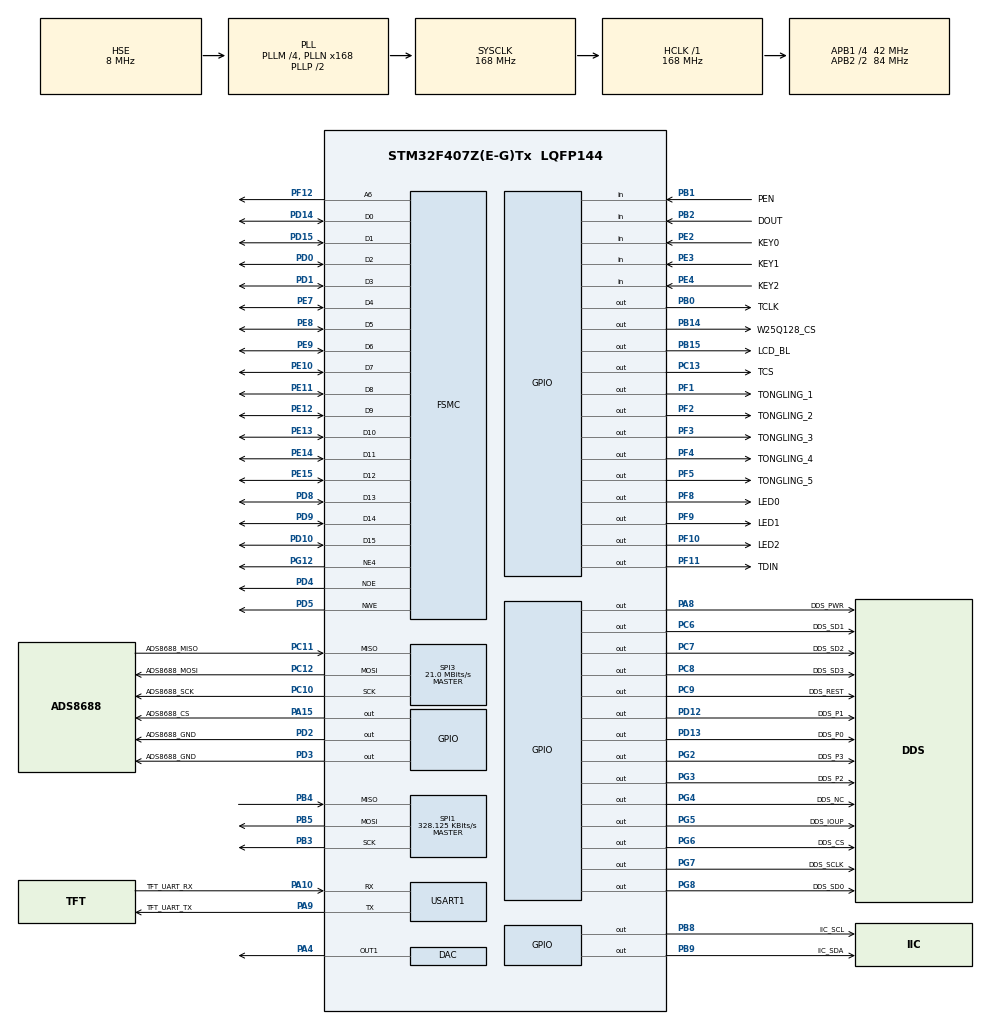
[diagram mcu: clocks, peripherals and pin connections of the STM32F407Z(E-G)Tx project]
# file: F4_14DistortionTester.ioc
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Dma.Request0=SPI3_RX
Dma.Request1=SPI3_TX
Dma.SPI3_RX.0.Direction=DMA_PERIPH_TO_MEMORY
Dma.SPI3_RX.0.FIFOMode=DMA_FIFOMODE_DISABLE
Dma.SPI3_RX.0.Instance=DMA1_Stream0
Dma.SPI3_RX.0.MemDataAlignment=DMA_MDATAALIGN_HALFWORD
Dma.SPI3_RX.0.MemInc=DMA_MINC_ENABLE
Dma.SPI3_RX.0.Mode=DMA_NORMAL
Dma.SPI3_RX.0.PeriphDataAlignment=DMA_PDATAALIGN_HALFWORD
Dma.SPI3_RX.0.PeriphInc=DMA_PINC_DISABLE
Dma.SPI3_RX.0.Priority=DMA_PRIORITY_LOW
Dma.SPI3_TX.1.Direction=DMA_MEMORY_TO_PERIPH
Dma.SPI3_TX.1.FIFOMode=DMA_FIFOMODE_DISABLE
Dma.SPI3_TX.1.Instance=DMA1_Stream5
Dma.SPI3_TX.1.MemDataAlignment=DMA_MDATAALIGN_HALFWORD
Dma.SPI3_TX.1.MemInc=DMA_MINC_ENABLE
Dma.SPI3_TX.1.Mode=DMA_NORMAL
Dma.SPI3_TX.1.PeriphDataAlignment=DMA_PDATAALIGN_HALFWORD
Dma.SPI3_TX.1.PeriphInc=DMA_PINC_DISABLE
Dma.SPI3_TX.1.Priority=DMA_PRIORITY_LOW
FREERTOS.CountingSemaphores01=TFT_RX_LED,10,Dynamic,NULL;TFT_TX_LED,10,Dynamic,NULL
FREERTOS.Queues01=USART1_RX,5,30,1,Dynamic,NULL,NULL
FREERTOS.Tasks01=defaultTask,8,128,StartDefaultTask,Default,NULL,Dynamic,NULL,NULL;LED0_Toggle,48,128,StartLED0Toggle,As weak,NULL,Dynamic,NULL,NULL;LED1_Toggle,48,128,StartLED1Toggle,As weak,NULL,Dynamic,NULL,NULL;TFT_CMD_Process,40,256,TFT_CMD_Process_Start,As weak,NULL,Dynamic,NULL,NULL;FLASH_Data_Auto,24,128,FLASH_Data_AutoUpdate_Start,As weak,NULL,Dynamic,NULL,NULL;LED2_Toggle,48,128,StartLED2Toggle,As weak,NULL,Dynamic,NULL,NULL;MainTask,39,1024,MainTask_Start,As weak,NULL,Dynamic,NULL,NULL
FREERTOS.configENABLE_FPU=1
FREERTOS.configUSE_NEWLIB_REENTRANT=1
FSMC.AddressSetupTime1=0x0f
FSMC.BusTurnAroundDuration1=0
FSMC.DataSetupTime1=60
FSMC.ExtendedAddressSetupTime1=9
FSMC.ExtendedBusTurnAroundDuration1=0
FSMC.ExtendedDataSetupTime1=8
FSMC.ExtendedMode1=FSMC_EXTENDED_MODE_ENABLE
Mcu.Family=STM32F4
Mcu.Name=STM32F407Z(E-G)Tx
Mcu.Package=LQFP144
NVIC.DMA1_Stream0_IRQn=true\:0\:0\:true\:false\:true\:false\:false\:true
NVIC.DMA1_Stream5_IRQn=true\:0\:0\:true\:false\:true\:false\:false\:true
NVIC.PriorityGroup=NVIC_PRIORITYGROUP_4
NVIC.TIM1_UP_TIM10_IRQn=true\:1\:0\:true\:false\:true\:false\:true\:true
NVIC.TIM2_IRQn=true\:4\:0\:true\:false\:true\:false\:false\:true
NVIC.TimeBase=TIM2_IRQn
NVIC.TimeBaseIP=TIM2
NVIC.USART1_IRQn=true\:6\:0\:true\:false\:true\:true\:true\:true
PA0-WKUP.Mode=SYS_WakeUp0
PA0-WKUP.Signal=SYS_WKUP
PA10.GPIO_Label=TFT_UART_RX
PA10.Mode=Asynchronous
PA10.Signal=USART1_RX
PA13.Mode=Serial_Wire
PA13.Signal=SYS_JTMS-SWDIO
PA14.Mode=Serial_Wire
PA14.Signal=SYS_JTCK-SWCLK
PA15.GPIO_Label=ADS8688_CS
PA15.GPIO_PuPd=GPIO_PULLUP
PA15.GPIO_Speed=GPIO_SPEED_FREQ_VERY_HIGH
PA15.PinState=GPIO_PIN_SET
PA15.Signal=GPIO_Output
PA4.Signal=COMP_DAC1_group
PA8.GPIO_Label=DDS_PWR
PA8.GPIO_Speed=GPIO_SPEED_FREQ_VERY_HIGH
PA8.Signal=GPIO_Output
PA9.GPIO_Label=TFT_UART_TX
PA9.Mode=Asynchronous
PA9.Signal=USART1_TX
PB0.GPIO_Label=TCLK
PB0.GPIO_PuPd=GPIO_PULLUP
PB0.GPIO_Speed=GPIO_SPEED_FREQ_VERY_HIGH
PB0.Signal=GPIO_Output
PB1.GPIO_Label=PEN
PB1.GPIO_Mode=GPIO_MODE_INPUT
PB1.GPIO_PuPd=GPIO_PULLUP
PB1.Signal=GPIO_Input
PB14.GPIO_Label=W25Q128_CS
PB14.GPIO_PuPd=GPIO_PULLUP
PB14.GPIO_Speed=GPIO_SPEED_FREQ_VERY_HIGH
PB14.PinState=GPIO_PIN_SET
PB14.Signal=GPIO_Output
PB15.GPIO_Label=LCD_BL
PB15.GPIO_PuPd=GPIO_PULLUP
PB15.GPIO_Speed=GPIO_SPEED_FREQ_MEDIUM
PB15.Signal=GPIO_Output
PB2.GPIO_Label=DOUT
PB2.GPIO_PuPd=GPIO_PULLUP
PB2.Signal=GPIO_Input
PB3.GPIO_PuPd=GPIO_PULLUP
PB3.GPIO_Speed=GPIO_SPEED_FREQ_VERY_HIGH
PB3.Mode=Full_Duplex_Master
PB3.Signal=SPI1_SCK
PB4.GPIO_PuPd=GPIO_PULLUP
PB4.GPIO_Speed=GPIO_SPEED_FREQ_VERY_HIGH
PB4.Mode=Full_Duplex_Master
PB4.Signal=SPI1_MISO
PB5.GPIO_PuPd=GPIO_PULLUP
PB5.GPIO_Speed=GPIO_SPEED_FREQ_VERY_HIGH
PB5.Mode=Full_Duplex_Master
PB5.Signal=SPI1_MOSI
PB8.GPIO_Label=IIC_SCL
PB8.GPIO_PuPd=GPIO_PULLUP
PB8.GPIO_Speed=GPIO_SPEED_FREQ_VERY_HIGH
PB8.Signal=GPIO_Output
PB9.GPIO_Label=IIC_SDA
PB9.GPIO_PuPd=GPIO_PULLUP
PB9.GPIO_Speed=GPIO_SPEED_FREQ_VERY_HIGH
PB9.Signal=GPIO_Output
PC10.GPIO_Label=ADS8688_SCK
PC10.Mode=Full_Duplex_Master
PC10.Signal=SPI3_SCK
PC11.GPIO_Label=ADS8688_MISO
PC11.Mode=Full_Duplex_Master
PC11.Signal=SPI3_MISO
PC12.GPIO_Label=ADS8688_MOSI
PC12.Mode=Full_Duplex_Master
PC12.Signal=SPI3_MOSI
PC13-ANTI_TAMP.GPIO_Label=TCS
PC13-ANTI_TAMP.Signal=GPIO_Output
PC6.GPIO_Label=DDS_SD1
PC6.GPIO_Speed=GPIO_SPEED_FREQ_VERY_HIGH
PC6.Signal=GPIO_Output
PC7.GPIO_Label=DDS_SD2
PC7.GPIO_Speed=GPIO_SPEED_FREQ_VERY_HIGH
PC7.Signal=GPIO_Output
PC8.GPIO_Label=DDS_SD3
PC8.GPIO_Speed=GPIO_SPEED_FREQ_VERY_HIGH
PC8.Signal=GPIO_Output
PC9.GPIO_Label=DDS_REST
PC9.GPIO_Speed=GPIO_SPEED_FREQ_VERY_HIGH
PC9.Signal=GPIO_Output
PD0.GPIO_PuPd=GPIO_PULLUP
PD0.Signal=FSMC_D2_DA2
PD1.GPIO_PuPd=GPIO_PULLUP
PD1.Signal=FSMC_D3_DA3
PD10.GPIO_PuPd=GPIO_PULLUP
PD10.Signal=FSMC_D15_DA15
PD12.GPIO_Label=DDS_P1
PD12.GPIO_Speed=GPIO_SPEED_FREQ_VERY_HIGH
PD12.Signal=GPIO_Output
PD13.GPIO_Label=DDS_P0
PD13.GPIO_Speed=GPIO_SPEED_FREQ_VERY_HIGH
PD13.Signal=GPIO_Output
PD14.GPIO_PuPd=GPIO_PULLUP
PD14.Signal=FSMC_D0_DA0
PD15.GPIO_PuPd=GPIO_PULLUP
PD15.Signal=FSMC_D1_DA1
PD2.GPIO_Label=ADS8688_GND
PD2.Signal=GPIO_Output
PD3.GPIO_Label=ADS8688_GND
PD3.Signal=GPIO_Output
PD4.GPIO_PuPd=GPIO_PULLUP
PD4.Signal=FSMC_NOE
PD5.GPIO_PuPd=GPIO_PULLUP
PD5.Signal=FSMC_NWE
PD8.GPIO_PuPd=GPIO_PULLUP
PD8.Signal=FSMC_D13_DA13
PD9.GPIO_PuPd=GPIO_PULLUP
PD9.Signal=FSMC_D14_DA14
PE10.GPIO_PuPd=GPIO_PULLUP
PE10.Signal=FSMC_D7_DA7
PE11.GPIO_PuPd=GPIO_PULLUP
PE11.Signal=FSMC_D8_DA8
PE12.GPIO_PuPd=GPIO_PULLUP
PE12.Signal=FSMC_D9_DA9
PE13.GPIO_PuPd=GPIO_PULLUP
PE13.Signal=FSMC_D10_DA10
PE14.GPIO_PuPd=GPIO_PULLUP
PE14.Signal=FSMC_D11_DA11
PE15.GPIO_PuPd=GPIO_PULLUP
PE15.Signal=FSMC_D12_DA12
PE2.GPIO_Label=KEY0
PE2.GPIO_PuPd=GPIO_PULLUP
PE2.Signal=GPIO_Input
PE3.GPIO_Label=KEY1
PE3.GPIO_PuPd=GPIO_PULLUP
PE3.Signal=GPIO_Input
PE4.GPIO_Label=KEY2
PE4.GPIO_PuPd=GPIO_PULLUP
PE4.Signal=GPIO_Input
PE7.GPIO_PuPd=GPIO_PULLUP
PE7.Signal=FSMC_D4_DA4
PE8.GPIO_PuPd=GPIO_PULLUP
PE8.Signal=FSMC_D5_DA5
PE9.GPIO_PuPd=GPIO_PULLUP
PE9.Signal=FSMC_D6_DA6
PF1.GPIO_Label=TONGLING_1
PF1.GPIO_ModeDefaultOutputPP=GPIO_MODE_OUTPUT_OD
PF1.GPIO_PuPd=GPIO_PULLUP
PF1.GPIO_Speed=GPIO_SPEED_FREQ_VERY_HIGH
PF1.PinState=GPIO_PIN_SET
PF1.Signal=GPIO_Output
PF10.GPIO_Label=LED2
PF10.GPIO_ModeDefaultOutputPP=GPIO_MODE_OUTPUT_PP
PF10.GPIO_PuPd=GPIO_PULLUP
PF10.GPIO_Speed=GPIO_SPEED_FREQ_VERY_HIGH
PF10.PinState=GPIO_PIN_SET
PF10.Signal=GPIO_Output
PF11.GPIO_Label=TDIN
PF11.GPIO_Speed=GPIO_SPEED_FREQ_VERY_HIGH
PF11.Signal=GPIO_Output
PF12.GPIO_PuPd=GPIO_PULLUP
PF12.Signal=FSMC_A6
PF2.GPIO_Label=TONGLING_2
PF2.GPIO_ModeDefaultOutputPP=GPIO_MODE_OUTPUT_OD
PF2.GPIO_PuPd=GPIO_PULLUP
PF2.GPIO_Speed=GPIO_SPEED_FREQ_VERY_HIGH
PF2.PinState=GPIO_PIN_SET
PF2.Signal=GPIO_Output
PF3.GPIO_Label=TONGLING_3
PF3.GPIO_ModeDefaultOutputPP=GPIO_MODE_OUTPUT_OD
PF3.GPIO_PuPd=GPIO_PULLUP
PF3.GPIO_Speed=GPIO_SPEED_FREQ_VERY_HIGH
PF3.PinState=GPIO_PIN_SET
PF3.Signal=GPIO_Output
PF4.GPIO_Label=TONGLING_4
PF4.GPIO_ModeDefaultOutputPP=GPIO_MODE_OUTPUT_OD
PF4.GPIO_PuPd=GPIO_PULLUP
PF4.GPIO_Speed=GPIO_SPEED_FREQ_VERY_HIGH
PF4.PinState=GPIO_PIN_SET
PF4.Signal=GPIO_Output
PF5.GPIO_Label=TONGLING_5
PF5.GPIO_ModeDefaultOutputPP=GPIO_MODE_OUTPUT_OD
PF5.GPIO_PuPd=GPIO_PULLUP
PF5.GPIO_Speed=GPIO_SPEED_FREQ_VERY_HIGH
PF5.PinState=GPIO_PIN_SET
PF5.Signal=GPIO_Output
PF8.GPIO_Label=LED0
PF8.GPIO_ModeDefaultOutputPP=GPIO_MODE_OUTPUT_PP
PF8.GPIO_PuPd=GPIO_PULLUP
PF8.GPIO_Speed=GPIO_SPEED_FREQ_VERY_HIGH
PF8.PinState=GPIO_PIN_SET
PF8.Signal=GPIO_Output
PF9.GPIO_Label=LED1
PF9.GPIO_ModeDefaultOutputPP=GPIO_MODE_OUTPUT_PP
PF9.GPIO_PuPd=GPIO_PULLUP
PF9.GPIO_Speed=GPIO_SPEED_FREQ_VERY_HIGH
PF9.PinState=GPIO_PIN_SET
PF9.Signal=GPIO_Output
PG12.GPIO_PuPd=GPIO_PULLUP
PG12.Mode=NorPsramChipSelect4_1
PG12.Signal=FSMC_NE4
PG2.GPIO_Label=DDS_P3
PG2.GPIO_Speed=GPIO_SPEED_FREQ_VERY_HIGH
PG2.Signal=GPIO_Output
PG3.GPIO_Label=DDS_P2
PG3.GPIO_Speed=GPIO_SPEED_FREQ_VERY_HIGH
PG3.Signal=GPIO_Output
PG4.GPIO_Label=DDS_NC
PG4.GPIO_Speed=GPIO_SPEED_FREQ_VERY_HIGH
PG4.Signal=GPIO_Output
PG5.GPIO_Label=DDS_IOUP
PG5.GPIO_Speed=GPIO_SPEED_FREQ_VERY_HIGH
PG5.Signal=GPIO_Output
PG6.GPIO_Label=DDS_CS
PG6.GPIO_Speed=GPIO_SPEED_FREQ_VERY_HIGH
PG6.Signal=GPIO_Output
PG7.GPIO_Label=DDS_SCLK
PG7.GPIO_Speed=GPIO_SPEED_FREQ_VERY_HIGH
PG7.Signal=GPIO_Output
PG8.GPIO_Label=DDS_SD0
PG8.GPIO_Speed=GPIO_SPEED_FREQ_VERY_HIGH
PG8.Signal=GPIO_Output
PH0-OSC_IN.Mode=HSE-External-Oscillator
PH0-OSC_IN.Signal=RCC_OSC_IN
PH1-OSC_OUT.Mode=HSE-External-Oscillator
PH1-OSC_OUT.Signal=RCC_OSC_OUT
ProjectManager.HeapSize=0x200
ProjectManager.StackSize=0x400
ProjectManager.TargetToolchain=STM32CubeIDE
RCC.48MHZClocksFreq_Value=84000000
RCC.AHBFreq_Value=168000000
RCC.APB1CLKDivider=RCC_HCLK_DIV4
RCC.APB1Freq_Value=42000000
RCC.APB1TimFreq_Value=84000000
RCC.APB2CLKDivider=RCC_HCLK_DIV2
RCC.APB2Freq_Value=84000000
RCC.APB2TimFreq_Value=168000000
RCC.CortexFreq_Value=168000000
RCC.HCLKFreq_Value=168000000
RCC.HSE_VALUE=8000000
RCC.HSI_VALUE=16000000
RCC.LSE_VALUE=32768
RCC.PLLM=4
RCC.PLLN=168
RCC.PLLSourceVirtual=RCC_PLLSOURCE_HSE
RCC.SYSCLKFreq_VALUE=168000000
RCC.SYSCLKSource=RCC_SYSCLKSOURCE_PLLCLK
RCC.VCOOutputFreq_Value=336000000
SH.COMP_DAC1_group.0=DAC_OUT1,DAC_OUT1
SH.FSMC_A6.0=FSMC_A6,A6_1
SH.FSMC_D0_DA0.0=FSMC_D0,16b-d1
SH.FSMC_D10_DA10.0=FSMC_D10,16b-d1
SH.FSMC_D11_DA11.0=FSMC_D11,16b-d1
SH.FSMC_D12_DA12.0=FSMC_D12,16b-d1
SH.FSMC_D13_DA13.0=FSMC_D13,16b-d1
SH.FSMC_D14_DA14.0=FSMC_D14,16b-d1
SH.FSMC_D15_DA15.0=FSMC_D15,16b-d1
SH.FSMC_D1_DA1.0=FSMC_D1,16b-d1
SH.FSMC_D2_DA2.0=FSMC_D2,16b-d1
SH.FSMC_D3_DA3.0=FSMC_D3,16b-d1
SH.FSMC_D4_DA4.0=FSMC_D4,16b-d1
SH.FSMC_D5_DA5.0=FSMC_D5,16b-d1
SH.FSMC_D6_DA6.0=FSMC_D6,16b-d1
SH.FSMC_D7_DA7.0=FSMC_D7,16b-d1
SH.FSMC_D8_DA8.0=FSMC_D8,16b-d1
SH.FSMC_D9_DA9.0=FSMC_D9,16b-d1
SH.FSMC_NOE.0=FSMC_NOE,Lcd1
SH.FSMC_NWE.0=FSMC_NWE,Lcd1
SPI1.BaudRatePrescaler=SPI_BAUDRATEPRESCALER_256
SPI1.CLKPhase=SPI_PHASE_2EDGE
SPI1.CLKPolarity=SPI_POLARITY_HIGH
SPI1.CalculateBaudRate=328.125 KBits/s
SPI1.Direction=SPI_DIRECTION_2LINES
SPI1.Mode=SPI_MODE_MASTER
SPI1.VirtualType=VM_MASTER
SPI3.BaudRatePrescaler=SPI_BAUDRATEPRESCALER_2
SPI3.CLKPhase=SPI_PHASE_2EDGE
SPI3.CalculateBaudRate=21.0 MBits/s
SPI3.DataSize=SPI_DATASIZE_16BIT
SPI3.Direction=SPI_DIRECTION_2LINES
SPI3.Mode=SPI_MODE_MASTER
SPI3.VirtualType=VM_MASTER
TIM1.Period=105-1
TIM1.Prescaler=25-1
USART1.VirtualMode=VM_ASYNC
VP_FREERTOS_VS_CMSIS_V2.Mode=CMSIS_V2
VP_SYS_VS_tim2.Mode=TIM2
VP_TIM1_VS_ClockSourceINT.Mode=Internal
board=custom

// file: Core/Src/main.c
/* USER CODE BEGIN Header */
/**
  ******************************************************************************
  * @file           : main.c
  * @brief          : Main program body
  ******************************************************************************
  * @attention
  *
  * <h2><center>&copy; Copyright (c) 2021 STMicroelectronics.
  * All rights reserved.</center></h2>
  *
  * This software component is licensed by ST under BSD 3-Clause license,
  * the "License"; You may not use this file except in compliance with the
  * License. You may obtain a copy of the License at:
  *                        opensource.org/licenses/BSD-3-Clause
  *
  ******************************************************************************
  */
/* USER CODE END Header */
#include "main.h"
#include "cmsis_os.h"
#include "dac.h"
#include "dma.h"
#include "spi.h"
#include "tim.h"
#include "usart.h"
#include "gpio.h"
#include "fsmc.h"

/* USER CODE BEGIN Includes */
#include "base.h"
#include "lcd.h"
#include "text.h"
#include "touch.h"
#include "w25qxx.h"
#include "data.h"
#include "hmi_user_uart.h"
#include "hmi_driver.h"
#include "ADS8688.h"
#include "AD9959.h"
#include "output.h"
#include "arm_math.h"
#include "arm_const_structs.h"
/* USER CODE END Includes */

/* USER CODE BEGIN PD */
#define TP_CHECK(x0,y0,x1,y1) tp_dev.x[0] > x0 && tp_dev.y[0] > y0 && tp_dev.x[0] < x1 && tp_dev.y[0] < y1

/* USER CODE END PD */

void SystemClock_Config(void);
void MX_FREERTOS_Init(void);

int main(void)
{

  /* MCU Configuration--------------------------------------------------------*/

  /* Reset of all peripherals, Initializes the Flash interface and the Systick. */
  HAL_Init();

  /* Configure the system clock */
  SystemClock_Config();

  /* Initialize all configured peripherals */
  MX_GPIO_Init();
  MX_DMA_Init();
  MX_FSMC_Init();
  MX_SPI1_Init();
  MX_USART1_UART_Init();
  MX_SPI3_Init();
  MX_DAC_Init();
  MX_TIM1_Init();
  /* USER CODE BEGIN 2 */
  W25QXX_Init();
  //LCD_Init();
  //font_init();
  //tp_dev.init();
  TFT_Init(&RxBuffer);
  DATA_INIT();
//  Init_AD9959();
//  Out_freq(2, 10);
//  Out_mV(2, 300);

  /* USER CODE END 2 */

  /* Init scheduler */
  osKernelInitialize();  /* Call init function for freertos objects (in freertos.c) */
  MX_FREERTOS_Init();
  /* Start scheduler */
  osKernelStart();

  /* We should never get here as control is now taken by the scheduler */
  /* Infinite loop */
  while (1)
  {

  }
}

void SystemClock_Config(void)
{
  RCC_OscInitTypeDef RCC_OscInitStruct = {0};
  RCC_ClkInitTypeDef RCC_ClkInitStruct = {0};

  /** Configure the main internal regulator output voltage
  */
  __HAL_RCC_PWR_CLK_ENABLE();
  __HAL_PWR_VOLTAGESCALING_CONFIG(PWR_REGULATOR_VOLTAGE_SCALE1);
  /** Initializes the RCC Oscillators according to the specified parameters
  * in the RCC_OscInitTypeDef structure.
  */
  RCC_OscInitStruct.OscillatorType = RCC_OSCILLATORTYPE_HSE;
  RCC_OscInitStruct.HSEState = RCC_HSE_ON;
  RCC_OscInitStruct.PLL.PLLState = RCC_PLL_ON;
  RCC_OscInitStruct.PLL.PLLSource = RCC_PLLSOURCE_HSE;
  RCC_OscInitStruct.PLL.PLLM = 4;
  RCC_OscInitStruct.PLL.PLLN = 168;
  RCC_OscInitStruct.PLL.PLLP = RCC_PLLP_DIV2;
  RCC_OscInitStruct.PLL.PLLQ = 4;
  if (HAL_RCC_OscConfig(&RCC_OscInitStruct) != HAL_OK)
  {
    Error_Handler();
  }
  /** Initializes the CPU, AHB and APB buses clocks
  */
  RCC_ClkInitStruct.ClockType = RCC_CLOCKTYPE_HCLK|RCC_CLOCKTYPE_SYSCLK
                              |RCC_CLOCKTYPE_PCLK1|RCC_CLOCKTYPE_PCLK2;
  RCC_ClkInitStruct.SYSCLKSource = RCC_SYSCLKSOURCE_PLLCLK;
  RCC_ClkInitStruct.AHBCLKDivider = RCC_SYSCLK_DIV1;
  RCC_ClkInitStruct.APB1CLKDivider = RCC_HCLK_DIV4;
  RCC_ClkInitStruct.APB2CLKDivider = RCC_HCLK_DIV2;

  if (HAL_RCC_ClockConfig(&RCC_ClkInitStruct, FLASH_LATENCY_5) != HAL_OK)
  {
    Error_Handler();
  }
}

void HAL_TIM_PeriodElapsedCallback(TIM_HandleTypeDef *htim)
{
  if (htim->Instance == TIM2) {
    HAL_IncTick();
  }
}

void Error_Handler(void)
{
  __disable_irq();
  while (1)
  {
  }
}

/************************ (C) COPYRIGHT STMicroelectronics *****END OF FILE****/

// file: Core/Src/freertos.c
/* USER CODE BEGIN Header */
/**
  ******************************************************************************
  * File Name          : freertos.c
  * Description        : Code for freertos applications
  ******************************************************************************
  * @attention
  *
  * <h2><center>&copy; Copyright (c) 2021 STMicroelectronics.
  * All rights reserved.</center></h2>
  *
  * This software component is licensed by ST under Ultimate Liberty license
  * SLA0044, the "License"; You may not use this file except in compliance with
  * the License. You may obtain a copy of the License at:
  *                             www.st.com/SLA0044
  *
  ******************************************************************************
  */
/* USER CODE END Header */

#include "FreeRTOS.h"
#include "task.h"
#include "main.h"
#include "cmsis_os.h"

/* USER CODE BEGIN PD */
#define TASK void (*)(void *)
/* USER CODE END PD */

/* Definitions for defaultTask */
osThreadId_t defaultTaskHandle;
const osThreadAttr_t defaultTask_attributes = {
  .name = "defaultTask",
  .stack_size = 128 * 4,
  .priority = (osPriority_t) osPriorityLow,
};
/* Definitions for LED0_Toggle */
osThreadId_t LED0_ToggleHandle;
const osThreadAttr_t LED0_Toggle_attributes = {
  .name = "LED0_Toggle",
  .stack_size = 128 * 4,
  .priority = (osPriority_t) osPriorityRealtime,
};
/* Definitions for LED1_Toggle */
osThreadId_t LED1_ToggleHandle;
const osThreadAttr_t LED1_Toggle_attributes = {
  .name = "LED1_Toggle",
  .stack_size = 128 * 4,
  .priority = (osPriority_t) osPriorityRealtime,
};
/* Definitions for TFT_CMD_Process */
osThreadId_t TFT_CMD_ProcessHandle;
const osThreadAttr_t TFT_CMD_Process_attributes = {
  .name = "TFT_CMD_Process",
  .stack_size = 256 * 4,
  .priority = (osPriority_t) osPriorityHigh,
};
/* Definitions for FLASH_Data_Auto */
osThreadId_t FLASH_Data_AutoHandle;
const osThreadAttr_t FLASH_Data_Auto_attributes = {
  .name = "FLASH_Data_Auto",
  .stack_size = 128 * 4,
  .priority = (osPriority_t) osPriorityNormal,
};
/* Definitions for LED2_Toggle */
osThreadId_t LED2_ToggleHandle;
const osThreadAttr_t LED2_Toggle_attributes = {
  .name = "LED2_Toggle",
  .stack_size = 128 * 4,
  .priority = (osPriority_t) osPriorityRealtime,
};
/* Definitions for MainTask */
osThreadId_t MainTaskHandle;
const osThreadAttr_t MainTask_attributes = {
  .name = "MainTask",
  .stack_size = 1024 * 4,
  .priority = (osPriority_t) osPriorityAboveNormal7,
};
/* Definitions for USART1_RX */
osMessageQueueId_t USART1_RXHandle;
const osMessageQueueAttr_t USART1_RX_attributes = {
  .name = "USART1_RX"
};
/* Definitions for TFT_RX_LED */
osSemaphoreId_t TFT_RX_LEDHandle;
const osSemaphoreAttr_t TFT_RX_LED_attributes = {
  .name = "TFT_RX_LED"
};
/* Definitions for TFT_TX_LED */
osSemaphoreId_t TFT_TX_LEDHandle;
const osSemaphoreAttr_t TFT_TX_LED_attributes = {
  .name = "TFT_TX_LED"
};

void StartDefaultTask(void *argument);
void StartLED0Toggle(void *argument);
void StartLED1Toggle(void *argument);
void TFT_CMD_Process_Start(void *argument);
void FLASH_Data_AutoUpdate_Start(void *argument);
void StartLED2Toggle(void *argument);
void MainTask_Start(void *argument);

void MX_FREERTOS_Init(void); /* (MISRA C 2004 rule 8.1) */

void MX_FREERTOS_Init(void) {

  /* Create the semaphores(s) */
  /* creation of TFT_RX_LED */
  TFT_RX_LEDHandle = osSemaphoreNew(10, 10, &TFT_RX_LED_attributes);

  /* creation of TFT_TX_LED */
  TFT_TX_LEDHandle = osSemaphoreNew(10, 10, &TFT_TX_LED_attributes);

  /* Create the queue(s) */
  /* creation of USART1_RX */
  USART1_RXHandle = osMessageQueueNew (5, 30, &USART1_RX_attributes);

  /* Create the thread(s) */
  /* creation of defaultTask */
  defaultTaskHandle = osThreadNew(StartDefaultTask, NULL, &defaultTask_attributes);

  /* creation of LED0_Toggle */
  LED0_ToggleHandle = osThreadNew(StartLED0Toggle, NULL, &LED0_Toggle_attributes);

  /* creation of LED1_Toggle */
  LED1_ToggleHandle = osThreadNew(StartLED1Toggle, NULL, &LED1_Toggle_attributes);

  /* creation of TFT_CMD_Process */
  TFT_CMD_ProcessHandle = osThreadNew(TFT_CMD_Process_Start, NULL, &TFT_CMD_Process_attributes);

  /* creation of FLASH_Data_Auto */
  FLASH_Data_AutoHandle = osThreadNew(FLASH_Data_AutoUpdate_Start, NULL, &FLASH_Data_Auto_attributes);

  /* creation of LED2_Toggle */
  LED2_ToggleHandle = osThreadNew(StartLED2Toggle, NULL, &LED2_Toggle_attributes);

  /* creation of MainTask */
  MainTaskHandle = osThreadNew(MainTask_Start, NULL, &MainTask_attributes);

}

void StartDefaultTask(void *argument)
{
  for(;;)
  {
    osDelay(1);
  }
}

__weak void StartLED0Toggle(void *argument)
{
  for(;;)
  {
    osDelay(1);
  }
}

__weak void StartLED1Toggle(void *argument)
{
  for(;;)
  {
    osDelay(1);
  }
}

__weak void TFT_CMD_Process_Start(void *argument)
{
  for(;;)
  {
    osDelay(1);
  }
}

__weak void FLASH_Data_AutoUpdate_Start(void *argument)
{
  for(;;)
  {
    osDelay(1);
  }
}

__weak void StartLED2Toggle(void *argument)
{
  for(;;)
  {
    osDelay(1);
  }
}

__weak void MainTask_Start(void *argument)
{
  for(;;)
  {
    osDelay(1);
  }
}

/************************ (C) COPYRIGHT STMicroelectronics *****END OF FILE****/
